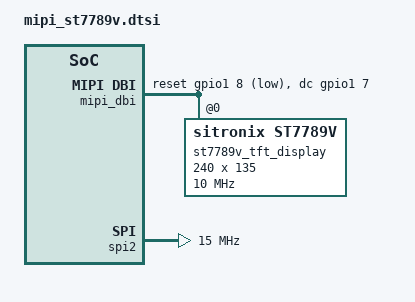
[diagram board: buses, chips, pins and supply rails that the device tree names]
/*
 * SPDX-FileCopyrightText: Copyright 2025 Sam Blenny
 * SPDX-License-Identifier: Apache-2.0
 *
 * Configure 240x135 px ST7789V display over MIPI bus (SPI + DC + RST)
 *
 * Related docs & reference code:
 * - https://docs.zephyrproject.org/latest/build/dts/api/bindings/mipi-dbi/zephyr%2Cmipi-dbi-spi.html
 * - https://docs.zephyrproject.org/4.0.0/build/dts/api/bindings/display/sitronix%2Cst7789v.html
 * - https://newhavendisplay.com/content/datasheets/ST7789V.pdf
 * - https://github.com/adafruit/Adafruit_CircuitPython_ST7789/blob/1.6.4/adafruit_st7789.py
 * - https://github.com/adafruit/circuitpython/blob/main/shared-bindings/busdisplay/BusDisplay.c
 * - https://github.com/adafruit/circuitpython/blob/main/shared-module/busdisplay/BusDisplay.c
 * - https://docs.circuitpython.org/en/latest/shared-bindings/busdisplay/
 * - https://learn.adafruit.com/adafruit-1-14-240x135-color-tft-breakout/circuitpython-displayio-quickstart
 *
 * The Feather TFT ESP32-S3 board uses the same display module as the Adafruit
 * 1.14" 240x135 Color TFT breakout board (Adafruit P/N: 4383). In the Learn
 * guide for that breakout board, the ST7789 DisplayIO driver gets initialized
 * with `width=240, height=135, rowstart=40, colstart=53`.
 */

#include <zephyr/dt-bindings/mipi_dbi/mipi_dbi.h>

&spi2 {
	/* Datasheet: min serial clock write cycle is 66 ns (15.15 MHz) */
	clock-frequency = <15000000>; /* 15 MHz */
};

/ {
	chosen {
		zephyr,display = &st7789v_tft_display;
	};

	mipi_dbi {
		compatible = "zephyr,mipi-dbi-spi";

		/* Configure spi device with DC and reset pins */
		spi-dev = <&spi2>;
		dc-gpios =    <&gpio1 7 GPIO_ACTIVE_HIGH>;  /* GPIO39 -> &gpio1 7 */
		reset-gpios = <&gpio1 8 GPIO_ACTIVE_LOW>;   /* GPIO40 -> &gpio1 8 */
		write-only;

		#address-cells = <1>;
		#size-cells = <0>;

		st7789v_tft_display: st7789v@0 {
			compatible = "sitronix,st7789v";
			reg = <0>;
			mipi-max-frequency = <10000000>;  /* 10 MHz */
			mipi-mode = "MIPI_DBI_MODE_SPI_4WIRE";
			colmod = <0x55>;  /* 16-bit 5-6-5 color */

			/* The combination of mdac, x-offset, y-offset, height, and width
			 * control screen rotation, RGB/BGR order, and refresh direction.
			 * The mdac property corresponds to the MIPI MADCTL command (36h).
			 *
			 * 0° rotation (top left by Feather TFT Boot button):
			 *   mdac     = <0x0C>;
			 *   x-offset = <52>;
			 *   y-offset = <40>;
			 *   height   = <240>;
			 *   width    = <135>;
			 *
			 * 90° CW rotation (top left by Feather TFT battery jack):
			 *   mdac     = <0x6C>;
			 *   x-offset = <40>;
			 *   y-offset = <53>;
			 *   height   = <135>;
			 *   width    = <240>;
			 *
			 * 180° CW rotation (top left by Feathe TFT SDA pin):
			 *   mdac     = <0xCC>;
			 *   x-offset = <53>;
			 *   y-offset = <40>;
			 *   height   = <240>;
			 *   width    = <135>;
			 *
			 * 270° CW rotation (top left by Feather TFT Adafruit logo):
			 *   mdac     = <0xAC>;
			 *   x-offset = <40>;
			 *   y-offset = <52>;
			 *   height   = <135>;
			 *   width    = <240>;
			 */

			/* 90° CW rotation (top left by Feather TFT battery jack) */
			mdac     = <0x6C>;
			x-offset = <40>;
			y-offset = <53>;
			height   = <135>;
			width    = <240>;

			/* Set required properties to defaults from ST7789V datasheet */
			vcom     = <0x20>;
			gctrl    = <0x35>;
			lcm      = <0x2C>;
			gamma    = <0x01>;
			porch-param   = [0C 0C 00 33 33];
			cmd2en-param  = [5A 69 02 00];
			pwctrl1-param = [A4 81];
			pvgam-param   = [d0 00 02 07 0b 1a 31 54 40 29 12 12 12 17];
			nvgam-param   = [d0 00 02 07 05 25 2d 44 44 1c 18 16 1c 1d];
			ram-param     = [00 f0];
			rgb-param     = [40 02 14];
		};
	};
};
